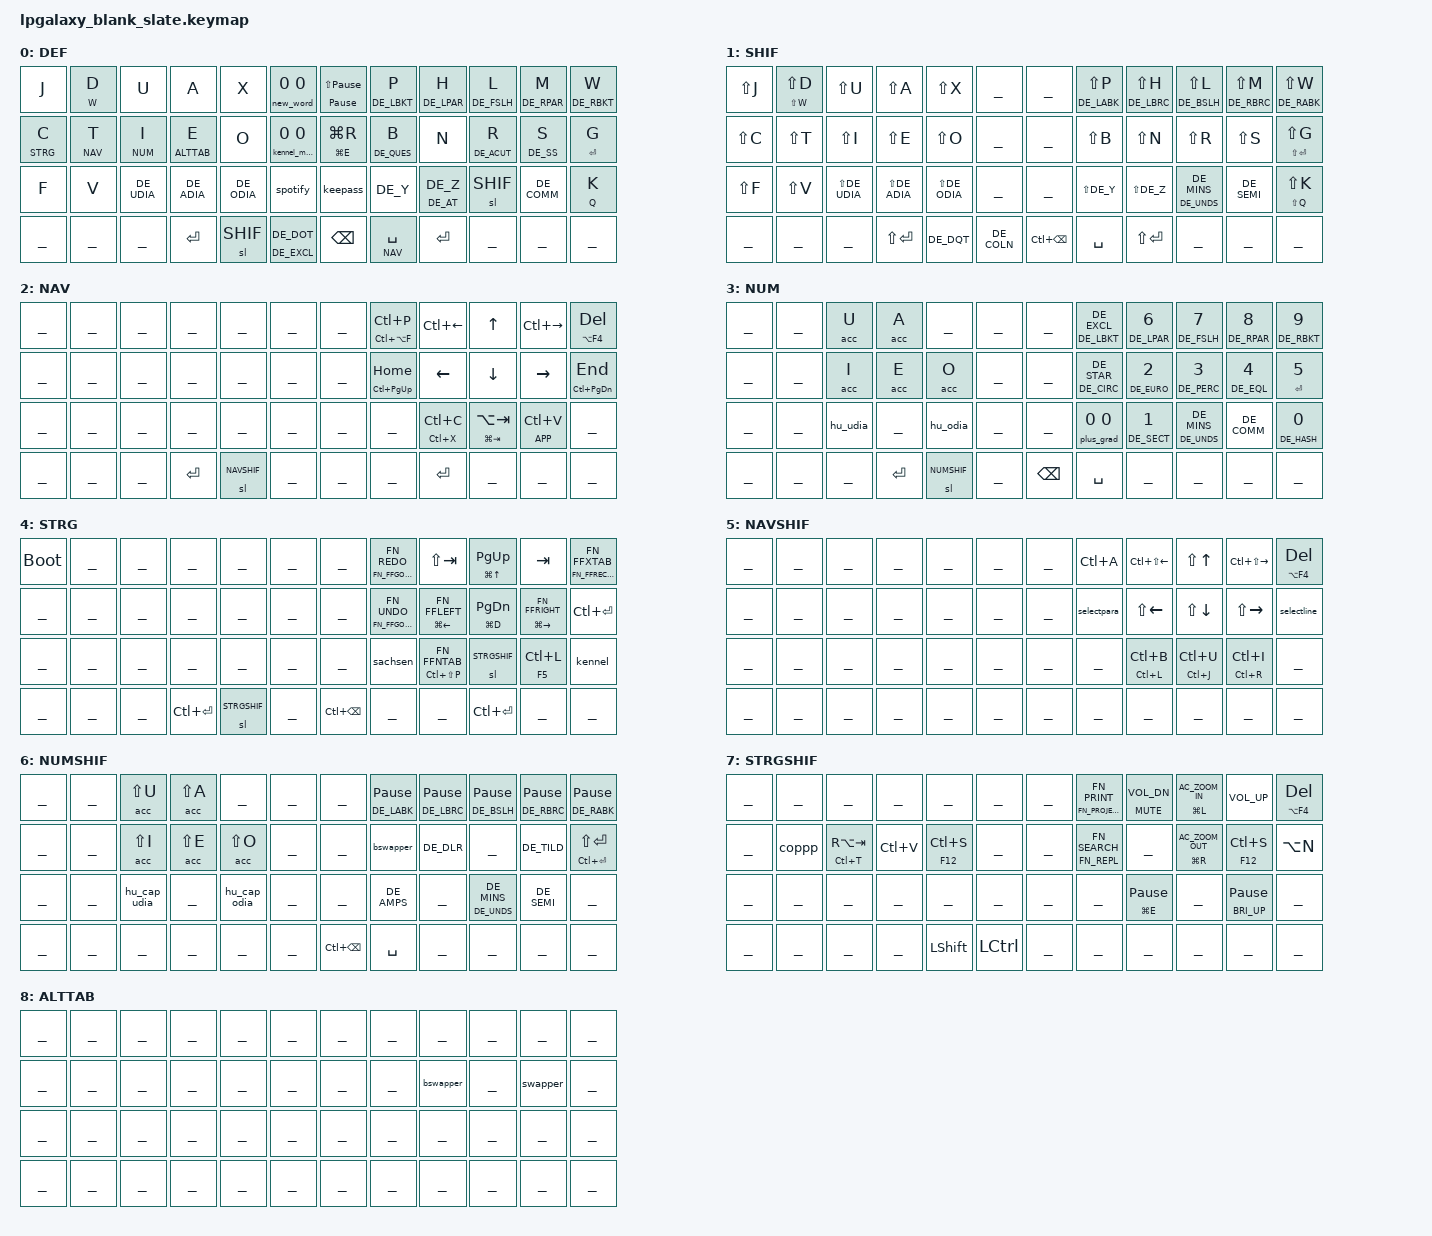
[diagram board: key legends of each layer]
#include <behaviors.dtsi>
#include <dt-bindings/zmk/keys.h>
#include <dt-bindings/zmk/bt.h>
#include <dt-bindings/zmk/outputs.h>

#define DEF         0
#define SHIF        1
#define NAV         2 
#define NUM         3
#define STRG        4
#define NAVSHIF     5
#define NUMSHIF     6  
#define STRGSHIF    7 
#define ALTTAB      8

#include "german.dtsi"
#include "functions.dtsi"
#include "helper.h"
#include "keypos.h"

#define KEYS_L LT5 LT4 LT3 LT2 LT1 LM5 LM4 LM3 LM2 LM1 LB5 LB4 LB3 LB2 LB1
#define KEYS_R RT1 RT2 RT3 RT4 RT5 RM1 RM2 RM3 RM4 RM5 RB1 RB2 RB3 RB4 RB5
#define THUMBS LH2 LH1 LH0 RH0 RH1    

#define BT(n) BT_SEL n

&lt {
            hold-trigger-key-positions = <KEYS_R THUMBS>;
            quick_tap_ms = <200>;
            flavor = "tap-preferred";
    };

/////////////// ALTTAB //////////////////////// 
ZMK_BEHAVIOR(swapper, tri_state,
    bindings = <&kt LALT>, <&kp TAB>, <&kt LALT>;)

ZMK_BEHAVIOR(bswapper, tri_state,
    bindings = <&kt LALT>, <&kp LS(TAB)>, <&kt LALT>;)

ZMK_COMBO(swit,  &kp RA(TAB), 20 21 22, ALL, 25)

/////////////// HOLDTABS //////////////////////// 
ZMK_BEHAVIOR(ht, hold_tap,
    flavor = "tap-preferred";
    tapping-term-ms = <250>;
    quick-tap-ms = <125>;
    bindings = <&kp>, <&kp>;)

ZMK_BEHAVIOR(plus_grad, hold_tap,
    flavor = "tap-preferred";
    tapping-term-ms = <250>;
    quick-tap-ms = <125>;
    bindings = <&grad>, <&plus>;)

ZMK_BEHAVIOR(kennel_mode, hold_tap,
    flavor = "balanced";
    tapping-term-ms = <250>;
    quick-tap-ms = <125>;
    bindings = <&mode>, <&kennel>;)

ZMK_BEHAVIOR(new_word, hold_tap,
    flavor = "balanced";
    tapping-term-ms = <250>;
    quick-tap-ms = <125>;
    bindings = <&word>, <&new>;)

/////////////// COMBOS //////////////////////// 
ZMK_COMBO(win,  &kp LGUI, 14 15, ALL, 25)
ZMK_COMBO(esc,  &kp ESC, 13 14, ALL, 25)
ZMK_COMBO(btab,  &kp LS(TAB), 8 9, ALL, 25)
ZMK_COMBO(tab,  &kp TAB, 9 10, ALL, 25)
ZMK_COMBO(profile1, &bt BT_SEL 1, 5 6, ALL, 25)
ZMK_COMBO(profile2, &bt BT_SEL 2, 17 18, ALL, 25)
ZMK_COMBO(profile3, &bt BT_SEL 3, 29 30, ALL, 25)
ZMK_COMBO(btclea, &bt BT_CLR_ALL, 5 17 29, ALL, 25)
ZMK_COMBO(banana, &sl STRGSHIF, LT5 LH1, ALL, 125)

/////////////// TAPDANCE //////////////////////// 
ZMK_BEHAVIOR(coppp, tap_dance,
    tapping-term-ms = <300>;
    bindings = <&kp LC(C)>, <&kp LG(LS(S))>, <&kp LG(LS(T))>;)

/////////////// STEUERUNG ////////////////////////   
ZMK_BEHAVIOR(selectline, macro,
    wait-ms = <100>;
    tap-ms = <5>;
    bindings = <&macro_tap &kp HOME>
                , <&macro_press &kp LSHFT>
                , <&macro_tap &kp END>
                , <&macro_release &kp LSHFT>
                ;)

ZMK_BEHAVIOR(selectpara, macro,
    wait-ms = <100>;
    tap-ms = <5>;
    bindings = <&macro_tap &kp LC(PG_UP)>
                , <&macro_press &kp LSHFT>
                , <&macro_tap &kp LC(PG_DN)>
                , <&macro_release &kp LSHFT>
                ;)

ZMK_BEHAVIOR(new, macro,
    wait-ms = <100>;
    tap-ms = <5>;
    bindings = <&macro_tap &kp LC(N)>
                ;)

/////////////// SYMBOLE //////////////////////// 
ZMK_BEHAVIOR(plus, macro,
    wait-ms = <100>;
    tap-ms = <5>;
    bindings = <&macro_tap &kp PLUS>
                ;)

ZMK_BEHAVIOR(grad, macro,
    wait-ms = <100>;
    tap-ms = <5>;
    bindings = <&macro_tap &kp B>
                , <&macro_tap &kp SPACE>
                , <&macro_tap &kp LS(C)>
                ;)

/////////////// UNGARISCH ////////////////////////
ZMK_BEHAVIOR(acc, macro_one_param, //(!)
    wait-ms = <100>;
    tap-ms = <5>;
    bindings = <&macro_tap &kp DE_ACUT>
                , <&macro_param_1to1>
                , <&kp MACRO_PLACEHOLDER>
                ;)

ZMK_BEHAVIOR(hu_odia, macro,
    wait-ms = <100>;
    tap-ms = <5>;
    bindings = <&macro_press &kp RALT>
                , <&macro_tap &kp KP_N0>
                , <&macro_tap &kp KP_N3>
                , <&macro_tap &kp KP_N3>
                , <&macro_tap &kp KP_N7>
                , <&macro_release &kp RALT>
                ;)

ZMK_BEHAVIOR(hu_cap_odia, macro,
    wait-ms = <100>;
    tap-ms = <5>;
    bindings = <&macro_press &kp RALT>
                , <&macro_tap &kp KP_N0>
                , <&macro_tap &kp KP_N3>
                , <&macro_tap &kp KP_N3>
                , <&macro_tap &kp KP_N6>
                , <&macro_release &kp RALT>
                ;)

ZMK_BEHAVIOR(hu_udia, macro,
    wait-ms = <100>;
    tap-ms = <5>;
    bindings = <&macro_press &kp RALT>
                , <&macro_tap &kp KP_N0>
                , <&macro_tap &kp KP_N3>
                , <&macro_tap &kp KP_N6>
                , <&macro_tap &kp KP_N9>
                , <&macro_release &kp RALT>
                ;)

ZMK_BEHAVIOR(hu_cap_udia, macro,
    wait-ms = <100>;
    tap-ms = <5>;
    bindings = <&macro_press &kp RALT>
                , <&macro_tap &kp KP_N0>
                , <&macro_tap &kp KP_N3>
                , <&macro_tap &kp KP_N6>
                , <&macro_tap &kp KP_N8>
                , <&macro_release &kp RALT>
                ;)

/////////////// TEXT ////////////////////////
ZMK_BEHAVIOR(mode, macro,
    wait-ms = <100>;
    tap-ms = <5>;
    bindings = <&macro_tap &kp O &kp L &kp I &kp V &kp E &kp R &kp DOT &kp K &kp E &kp N &kp N &kp E &kp L>
                , <&macro_press &kp RALT>
                , <&macro_tap &kp Q>
                , <&macro_release &kp RALT>
                , <&macro_tap &kp M &kp O &kp D &kp E &kp S &kp C &kp H &kp U &kp L &kp E &kp DE_MINS &kp B &kp E &kp R &kp L &kp I &kp N &kp DOT &kp D &kp E>
                ;)

ZMK_BEHAVIOR(kennel, macro,
    wait-ms = <100>;
    tap-ms = <5>;
    bindings = <&macro_tap &kp K &kp E &kp N &kp N &kp E &kp L>
                , <&macro_press &kp RALT>
                , <&macro_tap &kp Q>
                , <&macro_release &kp RALT>
                , <&macro_tap &kp P &kp O &kp S &kp T &kp E &kp O &kp DOT &kp D &kp E>
                ;)

ZMK_BEHAVIOR(sachsen, macro,
    wait-ms = <100>;
    tap-ms = <5>;
    bindings = <&macro_tap &kp LS(S) &kp DE_ADIA &kp C &kp H &kp S &kp I &kp S &kp C &kp E &kp SPACE &kp LS(S) &kp T &kp R &kp DOT &kp SPACE &kp N3 &kp N6>
                ;)

/////////////// APPS ÖFFNEN //////////////////////// 
ZMK_BEHAVIOR(spotify, macro,
    wait-ms = <100>;
    tap-ms = <5>;
    bindings = <&kp LGUI>
                , <&macro_wait_time 5>
                , <&kp S &kp P &kp O &kp T &kp I &kp F>
                , <&macro_wait_time 600>
                , <&kp ENTER>
                ;)

ZMK_BEHAVIOR(word, macro,
    wait-ms = <100>;
    tap-ms = <5>;
    bindings =  <&kp LGUI>
                , <&macro_wait_time 5>
                , <&kp W &kp I &kp N &kp W &kp O &kp R &kp D>
                , <&macro_wait_time 600>
                , <&macro_tap &kp ENTER>
                ;)

ZMK_BEHAVIOR(keepass, macro,
    wait-ms = <100>;
    tap-ms = <5>;
    bindings = <&kp LGUI>
                , <&macro_wait_time 5>
                , <&kp K &kp E &kp E &kp P &kp A &kp S &kp S>
                , <&macro_wait_time 600>
                , <&kp ENTER>
                ;)

/ {
    chosen {
       zmk,matrix_transform = &ortho_transform;
    };

//#include "macros.dtsi"

    keymap {
        compatible = "zmk,keymap";

        def_layer {
            label = "DEF";
            bindings = <
&kp J &ht W D &kp U &kp A &kp X &new_word 0 0 &ht PAUSE_BREAK LS(PAUSE_BREAK)  &ht DE_LBKT P &ht DE_LPAR H &ht DE_FSLH L &ht DE_RPAR M &ht DE_RBKT W
&lt STRG C &lt NAV T &lt NUM I &lt ALTTAB E &kp O &kennel_mode 0 0 &ht LG(E) LG(R) &ht DE_QUES B &kp N &ht DE_ACUT R &ht DE_SS S &ht ENTER G //auf r einen Layer der für den swapper ist
&kp F &kp V &kp DE_UDIA &kp DE_ADIA &kp DE_ODIA &spotify &keepass &kp DE_Y &ht DE_AT DE_Z &sl SHIF &kp DE_COMM &ht Q K
___ ___ ___ &kp ENTER &sl SHIF &ht DE_EXCL DE_DOT &kp BSPC &lt NAV SPACE &kp ENTER ___ ___ ___
            >;
        };

        shif_layer {
            label = "SHIF";
            bindings = <
&kp LS(J) &ht LS(W) LS(D) &kp LS(U) &kp LS(A) &kp LS(X) ___ ___ &ht DE_LABK LS(P) &ht DE_LBRC LS(H) &ht DE_BSLH LS(L) &ht DE_RBRC LS(M) &ht DE_RABK LS(W)
&kp LS(C)  &kp LS(T) &kp LS(I) &kp LS(E)  &kp LS(O) ___ ___ &kp LS(B) &kp LS(N) &kp LS(R)  &kp LS(S) &ht LS(ENTER) LS(G)
&kp LS(F) &kp LS(V) &kp LS(DE_UDIA) &kp LS(DE_ADIA) &kp LS(DE_ODIA) ___ ___ &kp LS(DE_Y) &kp LS(DE_Z) &ht DE_UNDS DE_MINS &kp DE_SEMI &ht LS(Q) LS(K)
___ ___ ___ &kp LS(ENTER) &kp DE_DQT &kp DE_COLN &kp LC(BSPC) &kp SPACE &kp LS(ENTER) ___ ___ ___
            >;
        };

        nav_layer {
            label = "NAV";
            bindings = <
___ ___ ___ ___ ___ ___ ___ &ht LC(LA(F)) LC(P) &kp LC(LEFT) &kp UP &kp LC(RIGHT) &ht LA(F4) DEL
___ ___ ___ ___ ___ ___ ___ &ht LC(PG_UP) HOME &kp  LEFT &kp DOWN &kp RIGHT &ht LC(PG_DN) END
___ ___ ___ ___ ___ ___ ___ ___ &ht LC(X) LC(C)  &ht LG(TAB) LA(TAB) &ht K_APP LC(V) ___
___ ___ ___ &kp ENTER &sl NAVSHIF ___ ___ ___ &kp ENTER ___ ___ ___ 
            >;
        };

        num_layer {
            label = "NUM";
            bindings = <
___ ___ &acc U &acc A ___ ___ ___ &ht DE_LBKT DE_EXCL &ht DE_LPAR N6 &ht DE_FSLH N7 &ht DE_RPAR N8 &ht DE_RBKT N9
___ ___ &acc I &acc E &acc O ___ ___  &ht DE_CIRC DE_STAR &ht DE_EURO N2 &ht DE_PERC N3 &ht DE_EQL N4 &ht ENTER N5
___ ___ &hu_udia ___ &hu_odia ___ ___ &plus_grad 0 0 &ht DE_SECT N1 &ht DE_UNDS DE_MINS &kp DE_COMM &ht DE_HASH N0
___ ___ ___ &kp ENTER &sl NUMSHIF ___ &kp BSPC &kp SPACE ___ ___ ___ ___ 
            >;
        };

        strg_layer {
            label = "STRG";
            bindings = <
&bootloader ___ ___ ___ ___ ___ ___ &ht FN_FFGOFORTH FN_REDO	&kp LS(TAB)	&ht LG(UP) PG_UP	&kp TAB	&ht FN_FFRECOV FN_FFXTAB
___ ___ ___ ___ ___ ___ ___ &ht FN_FFGOBACK FN_UNDO	&ht LG(LEFT) FN_FFLEFT	&ht LG(D) PG_DN	&ht LG(RIGHT) FN_FFRIGHT	&kp LC(ENTER)
___ ___ ___ ___ ___ ___ ___ &sachsen	&ht LC(LS(P)) FN_FFNTAB	&sl STRGSHIF	&ht F5 LC(L)	&kennel
___ ___ ___ &kp LC(ENTER) &sl STRGSHIF ___ &kp LC(BSPC) ___ ___ &kp LC(ENTER) ___ ___ 
            >;
        };

        navshif_layer {
            label = "NAVSHIF";
            bindings = <
___ ___ ___ ___ ___ ___ ___ &kp LC(A) &kp LC(LS(LEFT)) &kp LS(UP) &kp LC(LS(RIGHT)) &ht LA(F4) DEL
___ ___ ___ ___ ___ ___ ___ &selectpara &kp  LS(LEFT) &kp LS(DOWN) &kp LS(RIGHT) &selectline
___ ___ ___ ___ ___ ___ ___ ___ &ht LC(L) LC(B) &ht LC(J) LC(U) &ht LC(R) LC(I) ___ 
___ ___ ___ ___ ___ ___ ___ ___ ___ ___ ___ ___ 
            >;
        };

        numshif_layer {
            label = "NUMSHIF";
            bindings = <
___ ___ &acc LS(U) &acc LS(A) ___ ___ ___ &ht DE_LABK PAUSE_BREAK &ht DE_LBRC  PAUSE_BREAK &ht DE_BSLH  PAUSE_BREAK &ht DE_RBRC  PAUSE_BREAK &ht DE_RABK PAUSE_BREAK
___ ___ &acc LS(I) &acc LS(E) &acc LS(O) ___ ___ &bswapper	&kp DE_DLR	___	&kp DE_TILD	&ht LC(ENTER) LS(ENTER)
___ ___ &hu_cap_udia ___ &hu_cap_odia ___ ___ &kp DE_AMPS ___	&ht DE_UNDS DE_MINS	&kp DE_SEMI ___
___ ___ ___ ___ ___ ___ &kp LC(BSPC) &kp SPACE ___ ___ ___ ___ 
            >;
        };

        strgshif_layer {
            label = "STRGSHIF";
            bindings = <
___ ___ ___ ___ ___ ___ ___                         &ht FN_PROJECT FN_PRINT	&ht C_MUTE C_VOL_DN	&ht LG(L) C_AC_ZOOM_IN	&kp C_VOL_UP	&ht LA(F4) DEL
___ &coppp &ht LC(T) RA(TAB) &kp LC(V) &ht F12 LC(S)  ___ ___ &ht FN_REPL FN_SEARCH	___	&ht LG(R) C_AC_ZOOM_OUT	 &ht F12 LC(S)	&kp LA(N)
___ ___ ___ ___ ___ ___ ___                      	___ &ht LG(E) PAUSE_BREAK	___	&ht C_BRI_UP PAUSE_BREAK	___
___ ___ ___                 ___ &kp LSHFT &kp LCTRL ___ ___ ___ ___ ___ ___
            >;
        }; 

        alttab_layer {
            label = "ALTTAB";
            bindings = <
___ ___ ___ ___ ___ ___ ___ ___ ___ ___ ___ ___
___ ___ ___ ___ ___ ___ ___ ___ &bswapper ___ &swapper ___
___ ___ ___ ___ ___ ___ ___ ___ ___ ___ ___ ___
___ ___ ___ ___ ___ ___ ___ ___ ___ ___ ___ ___
            >;
        };

    };
};

